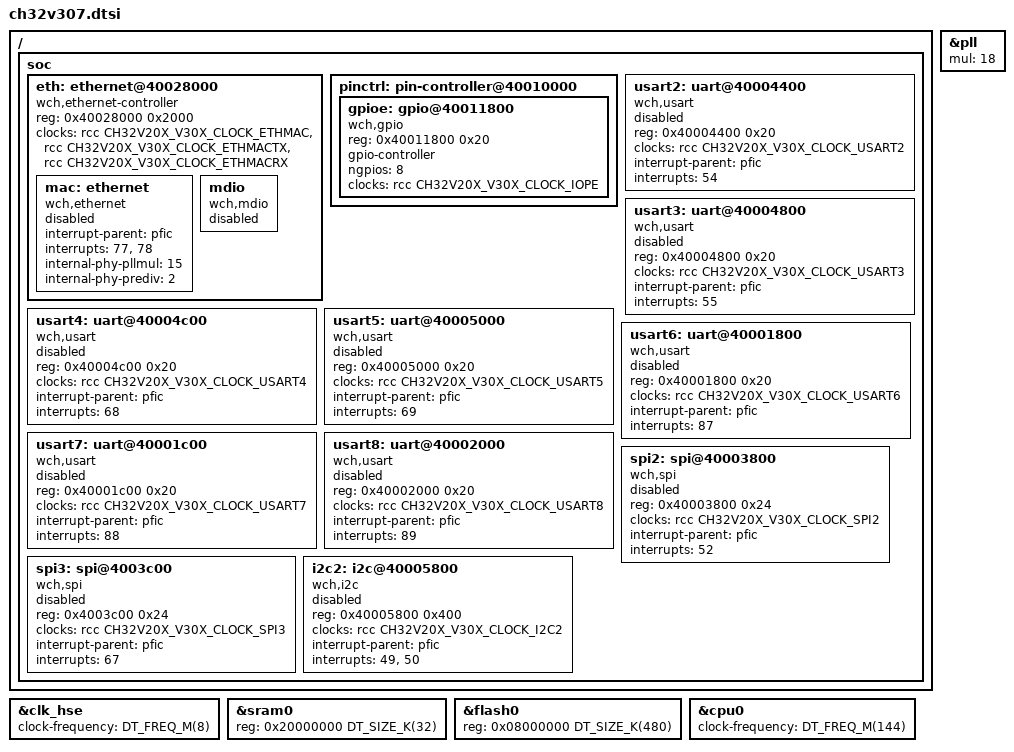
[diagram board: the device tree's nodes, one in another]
/*
 * Copyright (c) 2025 Thomas Boje
 *
 * SPDX-License-Identifier: Apache-2.0
 */

#include <wch/qingke-v4f.dtsi>
#include <wch/common/ch32v20x_30x_common.dtsi>

/ {
	soc {
		eth: ethernet@40028000 {
			reg = <0x40028000 0x2000>;
			compatible = "wch,ethernet-controller";
			clocks = <&rcc CH32V20X_V30X_CLOCK_ETHMAC>,
				 <&rcc CH32V20X_V30X_CLOCK_ETHMACTX>,
				 <&rcc CH32V20X_V30X_CLOCK_ETHMACRX>;
			clock-names = "mac", "tx", "rx";

			mac: ethernet {
				compatible = "wch,ethernet";
				interrupt-parent = <&pfic>;
				interrupts = <77>, <78>;
				internal-phy-pllmul = "15";
				internal-phy-prediv = "2";
				status = "disabled";
			};

			mdio: mdio {
				compatible = "wch,mdio";
				#address-cells = <1>;
				#size-cells = <0>;
				status = "disabled";
			};
		};

		pinctrl: pin-controller@40010000 {
			gpioe: gpio@40011800 {
				compatible = "wch,gpio";
				reg = <0x40011800 0x20>;
				gpio-controller;
				#gpio-cells = <2>;
				ngpios = <8>;
				clocks = <&rcc CH32V20X_V30X_CLOCK_IOPE>;
			};
		};

		usart2: uart@40004400 {
			compatible = "wch,usart";
			reg = <0x40004400 0x20>;
			clocks = <&rcc CH32V20X_V30X_CLOCK_USART2>;
			interrupt-parent = <&pfic>;
			interrupts = <54>;
			status = "disabled";
		};

		usart3: uart@40004800 {
			compatible = "wch,usart";
			reg = <0x40004800 0x20>;
			clocks = <&rcc CH32V20X_V30X_CLOCK_USART3>;
			interrupt-parent = <&pfic>;
			interrupts = <55>;
			status = "disabled";
		};

		usart4: uart@40004c00 {
			compatible = "wch,usart";
			reg = <0x40004c00 0x20>;
			clocks = <&rcc CH32V20X_V30X_CLOCK_USART4>;
			interrupt-parent = <&pfic>;
			interrupts = <68>;
			status = "disabled";
		};

		usart5: uart@40005000 {
			compatible = "wch,usart";
			reg = <0x40005000 0x20>;
			clocks = <&rcc CH32V20X_V30X_CLOCK_USART5>;
			interrupt-parent = <&pfic>;
			interrupts = <69>;
			status = "disabled";
		};

		usart6: uart@40001800 {
			compatible = "wch,usart";
			reg = <0x40001800 0x20>;
			clocks = <&rcc CH32V20X_V30X_CLOCK_USART6>;
			interrupt-parent = <&pfic>;
			interrupts = <87>;
			status = "disabled";
		};

		usart7: uart@40001c00 {
			compatible = "wch,usart";
			reg = <0x40001c00 0x20>;
			clocks = <&rcc CH32V20X_V30X_CLOCK_USART7>;
			interrupt-parent = <&pfic>;
			interrupts = <88>;
			status = "disabled";
		};

		usart8: uart@40002000 {
			compatible = "wch,usart";
			reg = <0x40002000 0x20>;
			clocks = <&rcc CH32V20X_V30X_CLOCK_USART8>;
			interrupt-parent = <&pfic>;
			interrupts = <89>;
			status = "disabled";
		};

		spi2: spi@40003800 {
			compatible = "wch,spi";
			reg = <0x40003800 0x24>;
			clocks = <&rcc CH32V20X_V30X_CLOCK_SPI2>;
			interrupt-parent = <&pfic>;
			interrupts = <52>;
			status = "disabled";
			#address-cells = <1>;
			#size-cells = <0>;
		};

		spi3: spi@4003c00 {
			compatible = "wch,spi";
			reg = <0x4003c00 0x24>;
			clocks = <&rcc CH32V20X_V30X_CLOCK_SPI3>;
			interrupt-parent = <&pfic>;
			interrupts = <67>;
			status = "disabled";
			#address-cells = <1>;
			#size-cells = <0>;
		};

		i2c2: i2c@40005800 {
			compatible = "wch,i2c";
			reg = <0x40005800 0x400>;
			clocks = <&rcc CH32V20X_V30X_CLOCK_I2C2>;
			interrupt-parent = <&pfic>;
			interrupts = <49>, <50>;
			status = "disabled";
			#address-cells = <1>;
			#size-cells = <0>;
		};
	};
};

&clk_hse {
	clock-frequency = <DT_FREQ_M(8)>;
};

&pll {
	mul = <18>;
};

&sram0 {
	reg = <0x20000000 DT_SIZE_K(32)>;
};

&flash0 {
	reg = <0x08000000 DT_SIZE_K(480)>;
};

&cpu0 {
	clock-frequency = <DT_FREQ_M(144)>;
};
